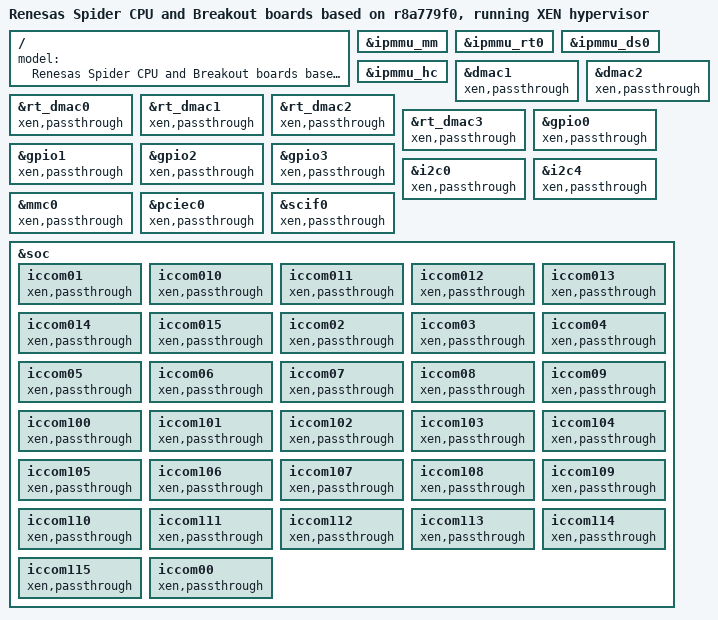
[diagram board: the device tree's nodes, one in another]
#include "r8a779f0-spider.dts"
#include "xen-chosen.dtsi"

/ {

	model = "Renesas Spider CPU and Breakout boards based on r8a779f0, running XEN hypervisor";
};

&ipmmu_mm {
	status = "okay";
};

&ipmmu_rt0 {
	status = "okay";
};


&ipmmu_ds0{
	status = "okay";
};

&ipmmu_hc {
	status = "okay";
};

&dmac1			{ xen,passthrough; };
&dmac2			{ xen,passthrough; };
&rt_dmac0		{ xen,passthrough; };
&rt_dmac1		{ xen,passthrough; };
&rt_dmac2		{ xen,passthrough; };
&rt_dmac3		{ xen,passthrough; };
&gpio0			{ xen,passthrough; };
&gpio1			{ xen,passthrough; };
&gpio2			{ xen,passthrough; };
&gpio3			{ xen,passthrough; };
&i2c0			{ xen,passthrough; };
&i2c4			{ xen,passthrough; };
&mmc0			{ xen,passthrough; };
&pciec0			{ xen,passthrough; };
&scif0			{ xen,passthrough; };

&soc {
	iccom01		{ xen,passthrough; };
	iccom010	{ xen,passthrough; };
	iccom011	{ xen,passthrough; };
	iccom012	{ xen,passthrough; };
	iccom013	{ xen,passthrough; };
	iccom014	{ xen,passthrough; };
	iccom015	{ xen,passthrough; };
	iccom02		{ xen,passthrough; };
	iccom03		{ xen,passthrough; };
	iccom04		{ xen,passthrough; };
	iccom05		{ xen,passthrough; };
	iccom06		{ xen,passthrough; };
	iccom07		{ xen,passthrough; };
	iccom08		{ xen,passthrough; };
	iccom09		{ xen,passthrough; };
	iccom100	{ xen,passthrough; };
	iccom101	{ xen,passthrough; };
	iccom102	{ xen,passthrough; };
	iccom103	{ xen,passthrough; };
	iccom104	{ xen,passthrough; };
	iccom105	{ xen,passthrough; };
	iccom106	{ xen,passthrough; };
	iccom107	{ xen,passthrough; };
	iccom108	{ xen,passthrough; };
	iccom109	{ xen,passthrough; };
	iccom110	{ xen,passthrough; };
	iccom111	{ xen,passthrough; };
	iccom112	{ xen,passthrough; };
	iccom113	{ xen,passthrough; };
	iccom114	{ xen,passthrough; };
	iccom115	{ xen,passthrough; };
	iccom00		{ xen,passthrough; };
};
